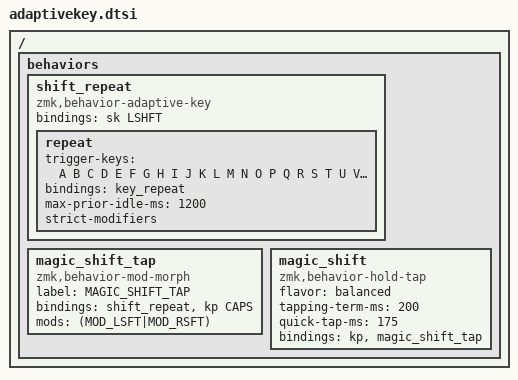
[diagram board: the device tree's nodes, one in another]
/ {
    behaviors {
        shift_repeat: shift_repeat {
            compatible = "zmk,behavior-adaptive-key";
            #binding-cells = <0>;
            bindings = <&sk LSHFT>;

            repeat {
                trigger-keys = <A B C D E F G H I J K L M N O P Q R S T U V W X Y Z>;
                bindings = <&key_repeat>;
                max-prior-idle-ms = <1200>;
                strict-modifiers;
            };
        };
        magic_shift_tap: magic_shift_tap  {
            compatible = "zmk,behavior-mod-morph";
            label = "MAGIC_SHIFT_TAP";
            bindings = <&shift_repeat>, <&kp CAPS>;

            #binding-cells = <0>;
            mods = <(MOD_LSFT|MOD_RSFT)>;
        };
        magic_shift: magic_shift {
            compatible = "zmk,behavior-hold-tap";
            #binding-cells = <2>;
            
            flavor = "balanced";
            tapping-term-ms = <200>;
            quick-tap-ms = <175>;
            bindings = <&kp>, <&magic_shift_tap>;
        };
    };
};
